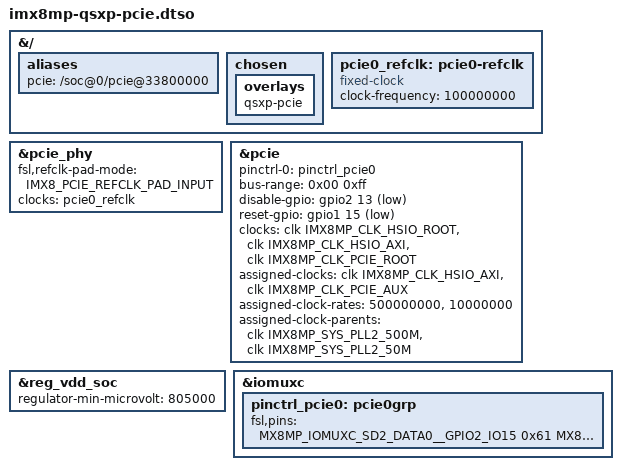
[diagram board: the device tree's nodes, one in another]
// SPDX-License-Identifier: (GPL-2.0 OR MIT)
/*
 * Copyright 2022 Lothar Waßmann <LW@KARO-electronics.de>
 *
 */

/dts-v1/;
/plugin/;

#include <dt-bindings/clock/imx8mp-clock.h>
#include <dt-bindings/gpio/gpio.h>
#include <dt-bindings/phy/phy-imx8-pcie.h>
#include "imx8mp-pinfunc.h"

&{/} {
	aliases {
		pcie = "/soc@0/pcie@33800000";
	};

	chosen {
		overlays {
			qsxp-pcie;
		};
	};

	pcie0_refclk: pcie0-refclk {
		compatible = "fixed-clock";
		#clock-cells = <0>;
		clock-frequency = <100000000>;
	};
};

&pcie_phy {
	fsl,refclk-pad-mode = <IMX8_PCIE_REFCLK_PAD_INPUT>;
	clocks = <&pcie0_refclk>;
	clock-names = "ref";
	status = "okay";
};

&pcie {
	pinctrl-names = "default";
	pinctrl-0 = <&pinctrl_pcie0>;
	bus-range = <0x00 0xff>;
	disable-gpio = <&gpio2 13 GPIO_ACTIVE_LOW>;
	reset-gpio = <&gpio1 15 GPIO_ACTIVE_LOW>;
	clocks = <&clk IMX8MP_CLK_HSIO_ROOT>,
		 <&clk IMX8MP_CLK_HSIO_AXI>,
		 <&clk IMX8MP_CLK_PCIE_ROOT>;
	clock-names = "pcie", "pcie_aux", "pcie_bus";
	assigned-clocks = <&clk IMX8MP_CLK_HSIO_AXI>,
			  <&clk IMX8MP_CLK_PCIE_AUX>;
	assigned-clock-rates = <500000000>, <10000000>;
	assigned-clock-parents = <&clk IMX8MP_SYS_PLL2_500M>,
				 <&clk IMX8MP_SYS_PLL2_50M>;
	status = "okay";
};

&reg_vdd_soc {
	/* PCIe requires a minimum vdd soc voltage of 0.805V */
	regulator-min-microvolt = <805000>;
};

&iomuxc {
	pinctrl_pcie0: pcie0grp {
		fsl,pins = <
			MX8MP_IOMUXC_SD2_DATA0__GPIO2_IO15	0x61 /* open drain, pull up */
			MX8MP_IOMUXC_SD2_CLK__GPIO2_IO13	0x41
			MX8MP_IOMUXC_GPIO1_IO15__GPIO1_IO15	0x41
		>;
	};
};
